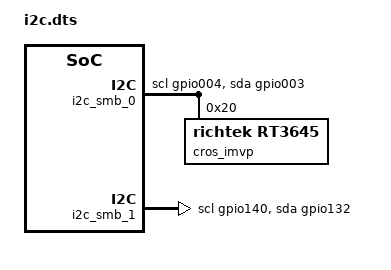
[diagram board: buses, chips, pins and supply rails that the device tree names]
/* Copyright 2024 The ChromiumOS Authors
 * Use of this source code is governed by a BSD-style license that can be
 * found in the LICENSE file.
 */

/* charger */
charger_i2c: &i2c_smb_0 {
	pinctrl-0 = <&i2c00_scl_gpio004 &i2c00_sda_gpio003>;
	pinctrl-names = "default";
	port-sel = <0>;
	scl-gpios = <MCHP_GPIO_DECODE_004 GPIO_OPEN_DRAIN>;
	sda-gpios = <MCHP_GPIO_DECODE_003 GPIO_OPEN_DRAIN>;


	cros_imvp: richtek-imvp@20 {
		compatible = "richtek,rt3645";
		status = "okay";
		reg = <0x20>;
	};
};

/* typec-aic1-power */
pd_pow_i2c: &i2c_smb_1 {
	pinctrl-0 = <&i2c06_scl_gpio140 &i2c06_sda_gpio132>;
	pinctrl-names = "default";
	port-sel = <6>;
	scl-gpios = <MCHP_GPIO_DECODE_140 GPIO_OPEN_DRAIN>;
	sda-gpios = <MCHP_GPIO_DECODE_132 GPIO_OPEN_DRAIN>;
};
